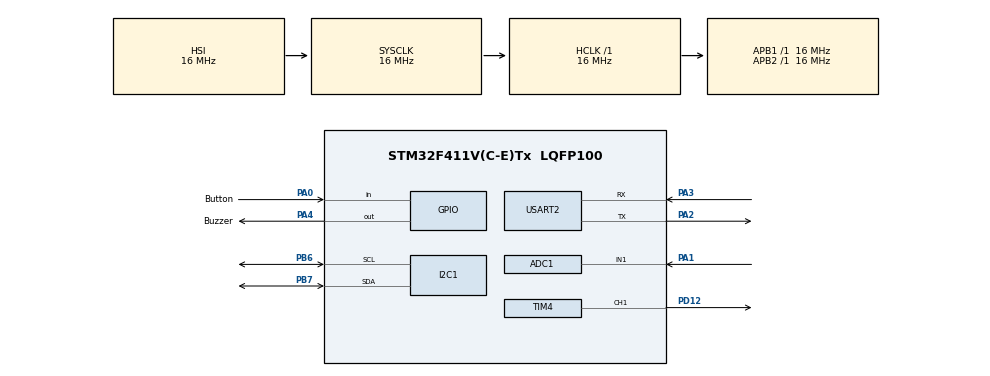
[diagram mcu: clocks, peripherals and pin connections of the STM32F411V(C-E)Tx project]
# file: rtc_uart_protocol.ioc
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ADC1.Channel-0\#ChannelRegularConversion=ADC_CHANNEL_1
ADC1.NbrOfConversionFlag=1
ADC1.Rank-0\#ChannelRegularConversion=1
ADC1.SamplingTime-0\#ChannelRegularConversion=ADC_SAMPLETIME_480CYCLES
ADC1.master=1
Dma.Request0=USART2_RX
Dma.USART2_RX.0.Direction=DMA_PERIPH_TO_MEMORY
Dma.USART2_RX.0.FIFOMode=DMA_FIFOMODE_DISABLE
Dma.USART2_RX.0.Instance=DMA1_Stream5
Dma.USART2_RX.0.MemDataAlignment=DMA_MDATAALIGN_BYTE
Dma.USART2_RX.0.MemInc=DMA_MINC_ENABLE
Dma.USART2_RX.0.Mode=DMA_CIRCULAR
Dma.USART2_RX.0.PeriphDataAlignment=DMA_PDATAALIGN_BYTE
Dma.USART2_RX.0.PeriphInc=DMA_PINC_DISABLE
Dma.USART2_RX.0.Priority=DMA_PRIORITY_LOW
Mcu.Family=STM32F4
Mcu.Name=STM32F411V(C-E)Tx
Mcu.Package=LQFP100
NVIC.ADC_IRQn=true\:0\:0\:false\:false\:true\:true\:true\:true
NVIC.DMA1_Stream5_IRQn=true\:0\:0\:false\:false\:true\:false\:true\:true
NVIC.PriorityGroup=NVIC_PRIORITYGROUP_4
NVIC.USART2_IRQn=true\:0\:0\:false\:false\:true\:true\:true\:true
PA0-WKUP.GPIO_Label=Button
PA0-WKUP.Signal=GPIO_Input
PA1.Signal=ADCx_IN1
PA13.Mode=Serial_Wire
PA13.Signal=SYS_JTMS-SWDIO
PA14.Mode=Serial_Wire
PA14.Signal=SYS_JTCK-SWCLK
PA2.Mode=Asynchronous
PA2.Signal=USART2_TX
PA3.Mode=Asynchronous
PA3.Signal=USART2_RX
PA4.GPIO_Label=Buzzer
PA4.PinState=GPIO_PIN_SET
PA4.Signal=GPIO_Output
PB6.Mode=I2C
PB6.Signal=I2C1_SCL
PB7.Mode=I2C
PB7.Signal=I2C1_SDA
PD12.Signal=S_TIM4_CH1
ProjectManager.HeapSize=0x200
ProjectManager.StackSize=0x400
ProjectManager.TargetToolchain=STM32CubeIDE
RCC.AHBFreq_Value=16000000
RCC.APB1Freq_Value=16000000
RCC.APB2Freq_Value=16000000
RCC.CortexFreq_Value=16000000
RCC.HSE_VALUE=25000000
RCC.HSI_VALUE=16000000
RCC.LSE_VALUE=32768
RCC.SYSCLKFreq_VALUE=16000000
RCC.VCOOutputFreq_Value=192000000
SH.ADCx_IN1.0=ADC1_IN1,IN1
SH.S_TIM4_CH1.0=TIM4_CH1,PWM Generation1 CH1
TIM4.AutoReloadPreload=TIM_AUTORELOAD_PRELOAD_DISABLE
TIM4.Channel-PWM\ Generation1\ CH1=TIM_CHANNEL_1
TIM4.Period=999
TIM4.Prescaler=7
TIM4.Pulse-PWM\ Generation1\ CH1=500
USART2.VirtualMode=VM_ASYNC
VP_TIM4_VS_ClockSourceINT.Mode=Internal
board=custom

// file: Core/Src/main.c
/* USER CODE BEGIN Header */
/**
 ******************************************************************************
 * @file           : main.c
 * @brief          : Main program body
 ******************************************************************************
 * @attention
 *
 * Copyright (c) 2024 STMicroelectronics.
 * All rights reserved.
 *
 * This software is licensed under terms that can be found in the LICENSE file
 * in the root directory of this software component.
 * If no LICENSE file comes with this software, it is provided AS-IS.
 *
 ******************************************************************************
 */
/* USER CODE END Header */
#include "main.h"

/* USER CODE BEGIN Includes */
#include "sys_buzzer.h"

/* USER CODE END Includes */

ADC_HandleTypeDef hadc1;

I2C_HandleTypeDef hi2c1;

TIM_HandleTypeDef htim4;

UART_HandleTypeDef huart2;
DMA_HandleTypeDef hdma_usart2_rx;

void SystemClock_Config(void);
static void MX_GPIO_Init(void);
static void MX_DMA_Init(void);
static void MX_I2C1_Init(void);
static void MX_USART2_UART_Init(void);
static void MX_ADC1_Init(void);
static void MX_TIM4_Init(void);

int main(void)
{

  /* MCU Configuration--------------------------------------------------------*/

  /* Reset of all peripherals, Initializes the Flash interface and the Systick. */
  HAL_Init();

  /* Configure the system clock */
  SystemClock_Config();

  /* Initialize all configured peripherals */
  MX_GPIO_Init();
  MX_DMA_Init();
  MX_I2C1_Init();
  MX_USART2_UART_Init();
  MX_ADC1_Init();
  MX_TIM4_Init();
  /* USER CODE BEGIN 2 */
  // sys_uart_init(&huart2);
  // sys_mng_init(&hi2c1);
  // sys_adc_uart_init(&huart2, &hadc1);
  sys_buzzer_init(&htim4, GPIOD, GPIO_PIN_12);

  /* USER CODE END 2 */

  /* Infinite loop */
  while (1)
  {

    /* USER CODE BEGIN 3 */
    // sys_uart_loop();
    // sys_mng_loop();
    // sys_adc_uart_loop();

    /* Check if button on PA0 is pressed */
    if (HAL_GPIO_ReadPin(GPIOA, GPIO_PIN_0) == GPIO_PIN_SET)
    {
      /* Turn on the buzzer */
      sys_buzzer_alarm(&htim4);
    }
  }
  /* USER CODE END 3 */
}

void SystemClock_Config(void)
{
  RCC_OscInitTypeDef RCC_OscInitStruct = {0};
  RCC_ClkInitTypeDef RCC_ClkInitStruct = {0};

  /** Configure the main internal regulator output voltage
  */
  __HAL_RCC_PWR_CLK_ENABLE();
  __HAL_PWR_VOLTAGESCALING_CONFIG(PWR_REGULATOR_VOLTAGE_SCALE1);

  /** Initializes the RCC Oscillators according to the specified parameters
  * in the RCC_OscInitTypeDef structure.
  */
  RCC_OscInitStruct.OscillatorType = RCC_OSCILLATORTYPE_HSI;
  RCC_OscInitStruct.HSIState = RCC_HSI_ON;
  RCC_OscInitStruct.HSICalibrationValue = RCC_HSICALIBRATION_DEFAULT;
  RCC_OscInitStruct.PLL.PLLState = RCC_PLL_NONE;
  if (HAL_RCC_OscConfig(&RCC_OscInitStruct) != HAL_OK)
  {
    Error_Handler();
  }

  /** Initializes the CPU, AHB and APB buses clocks
  */
  RCC_ClkInitStruct.ClockType = RCC_CLOCKTYPE_HCLK|RCC_CLOCKTYPE_SYSCLK
                              |RCC_CLOCKTYPE_PCLK1|RCC_CLOCKTYPE_PCLK2;
  RCC_ClkInitStruct.SYSCLKSource = RCC_SYSCLKSOURCE_HSI;
  RCC_ClkInitStruct.AHBCLKDivider = RCC_SYSCLK_DIV1;
  RCC_ClkInitStruct.APB1CLKDivider = RCC_HCLK_DIV1;
  RCC_ClkInitStruct.APB2CLKDivider = RCC_HCLK_DIV1;

  if (HAL_RCC_ClockConfig(&RCC_ClkInitStruct, FLASH_LATENCY_0) != HAL_OK)
  {
    Error_Handler();
  }
}

static void MX_ADC1_Init(void)
{

  ADC_ChannelConfTypeDef sConfig = {0};

  /** Configure the global features of the ADC (Clock, Resolution, Data Alignment and number of conversion)
  */
  hadc1.Instance = ADC1;
  hadc1.Init.ClockPrescaler = ADC_CLOCK_SYNC_PCLK_DIV2;
  hadc1.Init.Resolution = ADC_RESOLUTION_12B;
  hadc1.Init.ScanConvMode = DISABLE;
  hadc1.Init.ContinuousConvMode = DISABLE;
  hadc1.Init.DiscontinuousConvMode = DISABLE;
  hadc1.Init.ExternalTrigConvEdge = ADC_EXTERNALTRIGCONVEDGE_NONE;
  hadc1.Init.ExternalTrigConv = ADC_SOFTWARE_START;
  hadc1.Init.DataAlign = ADC_DATAALIGN_RIGHT;
  hadc1.Init.NbrOfConversion = 1;
  hadc1.Init.DMAContinuousRequests = DISABLE;
  hadc1.Init.EOCSelection = ADC_EOC_SINGLE_CONV;
  if (HAL_ADC_Init(&hadc1) != HAL_OK)
  {
    Error_Handler();
  }

  /** Configure for the selected ADC regular channel its corresponding rank in the sequencer and its sample time.
  */
  sConfig.Channel = ADC_CHANNEL_1;
  sConfig.Rank = 1;
  sConfig.SamplingTime = ADC_SAMPLETIME_480CYCLES;
  if (HAL_ADC_ConfigChannel(&hadc1, &sConfig) != HAL_OK)
  {
    Error_Handler();
  }

}

static void MX_I2C1_Init(void)
{

  hi2c1.Instance = I2C1;
  hi2c1.Init.ClockSpeed = 100000;
  hi2c1.Init.DutyCycle = I2C_DUTYCYCLE_2;
  hi2c1.Init.OwnAddress1 = 0;
  hi2c1.Init.AddressingMode = I2C_ADDRESSINGMODE_7BIT;
  hi2c1.Init.DualAddressMode = I2C_DUALADDRESS_DISABLE;
  hi2c1.Init.OwnAddress2 = 0;
  hi2c1.Init.GeneralCallMode = I2C_GENERALCALL_DISABLE;
  hi2c1.Init.NoStretchMode = I2C_NOSTRETCH_DISABLE;
  if (HAL_I2C_Init(&hi2c1) != HAL_OK)
  {
    Error_Handler();
  }

}

static void MX_TIM4_Init(void)
{

  TIM_ClockConfigTypeDef sClockSourceConfig = {0};
  TIM_MasterConfigTypeDef sMasterConfig = {0};
  TIM_OC_InitTypeDef sConfigOC = {0};

  htim4.Instance = TIM4;
  htim4.Init.Prescaler = 7;
  htim4.Init.CounterMode = TIM_COUNTERMODE_UP;
  htim4.Init.Period = 999;
  htim4.Init.ClockDivision = TIM_CLOCKDIVISION_DIV1;
  htim4.Init.AutoReloadPreload = TIM_AUTORELOAD_PRELOAD_DISABLE;
  if (HAL_TIM_Base_Init(&htim4) != HAL_OK)
  {
    Error_Handler();
  }
  sClockSourceConfig.ClockSource = TIM_CLOCKSOURCE_INTERNAL;
  if (HAL_TIM_ConfigClockSource(&htim4, &sClockSourceConfig) != HAL_OK)
  {
    Error_Handler();
  }
  if (HAL_TIM_PWM_Init(&htim4) != HAL_OK)
  {
    Error_Handler();
  }
  sMasterConfig.MasterOutputTrigger = TIM_TRGO_RESET;
  sMasterConfig.MasterSlaveMode = TIM_MASTERSLAVEMODE_DISABLE;
  if (HAL_TIMEx_MasterConfigSynchronization(&htim4, &sMasterConfig) != HAL_OK)
  {
    Error_Handler();
  }
  sConfigOC.OCMode = TIM_OCMODE_PWM1;
  sConfigOC.Pulse = 500;
  sConfigOC.OCPolarity = TIM_OCPOLARITY_HIGH;
  sConfigOC.OCFastMode = TIM_OCFAST_DISABLE;
  if (HAL_TIM_PWM_ConfigChannel(&htim4, &sConfigOC, TIM_CHANNEL_1) != HAL_OK)
  {
    Error_Handler();
  }
  HAL_TIM_MspPostInit(&htim4);

}

static void MX_USART2_UART_Init(void)
{

  huart2.Instance = USART2;
  huart2.Init.BaudRate = 115200;
  huart2.Init.WordLength = UART_WORDLENGTH_8B;
  huart2.Init.StopBits = UART_STOPBITS_1;
  huart2.Init.Parity = UART_PARITY_NONE;
  huart2.Init.Mode = UART_MODE_TX_RX;
  huart2.Init.HwFlowCtl = UART_HWCONTROL_NONE;
  huart2.Init.OverSampling = UART_OVERSAMPLING_16;
  if (HAL_UART_Init(&huart2) != HAL_OK)
  {
    Error_Handler();
  }

}

static void MX_DMA_Init(void)
{

  /* DMA controller clock enable */
  __HAL_RCC_DMA1_CLK_ENABLE();

  /* DMA interrupt init */
  /* DMA1_Stream5_IRQn interrupt configuration */
  HAL_NVIC_SetPriority(DMA1_Stream5_IRQn, 0, 0);
  HAL_NVIC_EnableIRQ(DMA1_Stream5_IRQn);

}

static void MX_GPIO_Init(void)
{
  GPIO_InitTypeDef GPIO_InitStruct = {0};

  /* GPIO Ports Clock Enable */
  __HAL_RCC_GPIOA_CLK_ENABLE();
  __HAL_RCC_GPIOD_CLK_ENABLE();
  __HAL_RCC_GPIOB_CLK_ENABLE();

  /*Configure GPIO pin Output Level */
  HAL_GPIO_WritePin(Buzzer_GPIO_Port, Buzzer_Pin, GPIO_PIN_SET);

  /*Configure GPIO pin : Button_Pin */
  GPIO_InitStruct.Pin = Button_Pin;
  GPIO_InitStruct.Mode = GPIO_MODE_INPUT;
  GPIO_InitStruct.Pull = GPIO_NOPULL;
  HAL_GPIO_Init(Button_GPIO_Port, &GPIO_InitStruct);

  /*Configure GPIO pin : Buzzer_Pin */
  GPIO_InitStruct.Pin = Buzzer_Pin;
  GPIO_InitStruct.Mode = GPIO_MODE_OUTPUT_PP;
  GPIO_InitStruct.Pull = GPIO_NOPULL;
  GPIO_InitStruct.Speed = GPIO_SPEED_FREQ_LOW;
  HAL_GPIO_Init(Buzzer_GPIO_Port, &GPIO_InitStruct);

}

void Error_Handler(void)
{
  __disable_irq();
  while (1)
  {
  }
}
